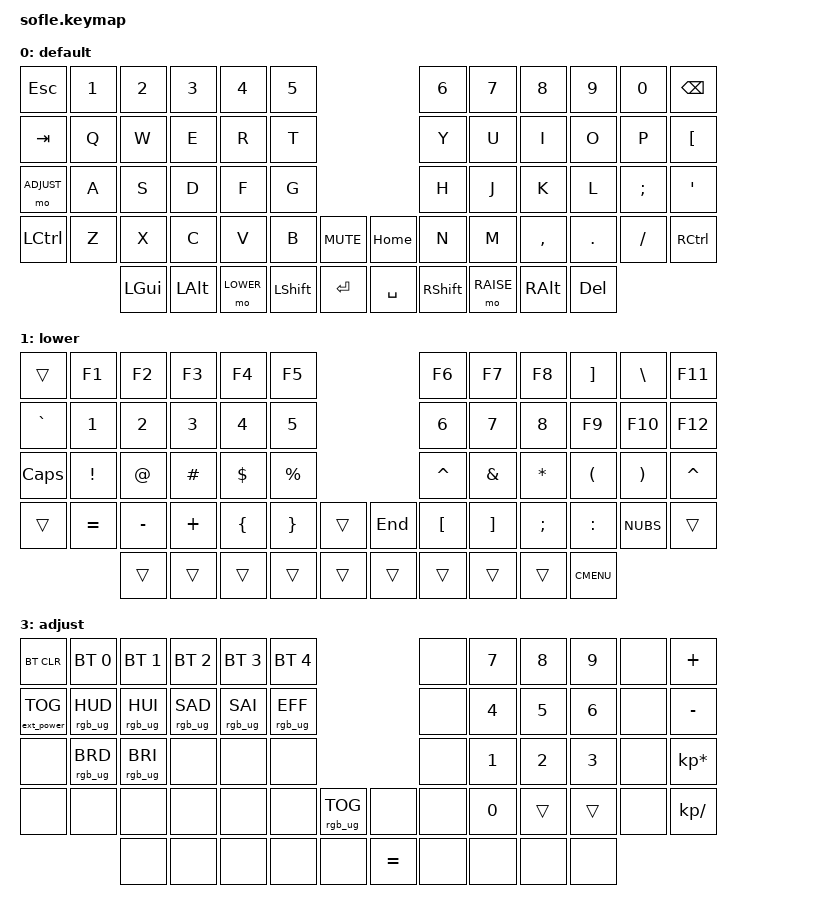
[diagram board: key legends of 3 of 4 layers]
/*
 * Copyright (c) 2020 The ZMK Contributors
 *
 * SPDX-License-Identifier: MIT
 */

#include <behaviors.dtsi>
#include <dt-bindings/zmk/keys.h>
#include <dt-bindings/zmk/bt.h>
#include <dt-bindings/zmk/rgb.h>
#include <dt-bindings/zmk/ext_power.h>

&left_encoder { resolution = <1>;};
&right_encoder { resolution = <1>;};

#define BASE 0
#define LOWER 1
#define RAISE 2
#define ADJUST 3

/ {

   // Activate ADJUST layer by pressing raise and lower
   // conditional_layers {
   //     compatible = "zmk,conditional-layers";
   //     adjust_layer {
   //         if-layers = <RAISE LOWER>;
   //         then-layer = <ADJUST>;
   //     };
   // };

    keymap {
        compatible = "zmk,keymap";

        default_layer {
            display-name = "default";
// ------------------------------------------------------------------------------------------------------------
// |  ESC  |  1  |  2  |  3   |  4   |  5   |                   |  6   |  7    |  8    |  9   |   0   | BKSPC |
// |  TAB  |  Q  |  W  |  E   |  R   |  T   |                   |  Y   |  U    |  I    |  O   |   P   |  []   |
// | ADJUST|  A  |  S  |  D   |  F   |  G   |                   |  H   |  J    |  K    |  L   |   ;   |   '   |
// | CTRL  |  Z  |  X  |  C   |  V   |  B   |  MUTE  |  |  HOME |  N   |  M    |  ,    |  .   |   /   | CTRL  |
//               | GUI | LALT | LOWER| SHIFT|  ENTER |  | SPACE | SHIFT| RAISE | RALT  | DEL  |
            bindings = <
&kp ESC   &kp N1 &kp N2   &kp N3   &kp N4    &kp N5                           &kp N6 &kp N7    &kp N8    &kp N9   &kp N0   &kp BSPC
&kp TAB   &kp Q  &kp W    &kp E    &kp R     &kp T                            &kp Y  &kp U     &kp I     &kp O    &kp P    &kp LBKT
&mo ADJUST &kp A  &kp S    &kp D    &kp F     &kp G                            &kp H  &kp J     &kp K     &kp L    &kp SEMI &kp APOS
&kp LCTRL &kp Z  &kp X    &kp C    &kp V     &kp B      &kp C_MUTE &kp HOME   &kp N  &kp M     &kp COMMA &kp DOT  &kp FSLH &kp RCTRL
                 &kp LGUI &kp LALT &mo LOWER &kp LSHFT  &kp RET   &kp SPACE  &kp RSHFT  &mo RAISE &kp RALT  &kp DEL
            >;

             sensor-bindings = <&inc_dec_kp C_VOL_DN C_VOL_UP &inc_dec_kp UP DOWN>;
        };

        lower_layer {
            display-name = "lower";
// TODO: Some binds are waiting for shifted keycode support.
// ------------------------------------------------------------------------------------------------------------
// |       |  F1 |  F2 |  F3  |  F4  |  F5  |                   |  F6  |  F7   |  F8   |  [   |   ]   |  F11  |
// |   `   |  1  |  2  |  3   |  4   |  5   |                   |   6  |  7    |  8    |  F9  |   F10 |  F12  |
// | CAPS  |  !  |  @  |  #   |  $   |  %   |                   |  ^   |  &    |  *    |  (   |   )   |   ¨   |
// |       |  =  |  -  |  +   |  {   |  }   |        |  |  END  |  [   |  ]    |  ;    |  :   |   \   |       |
//               |     |      |      |      |        |  |       |      |       |       | MENU |
            bindings = <
&trans    &kp F1    &kp F2    &kp F3      &kp F4    &kp F5                    &kp F6    &kp F7   &kp F8    &kp RBKT  &kp BSLH  &kp F11
&kp GRAVE &kp N1    &kp N2    &kp N3      &kp N4    &kp N5                    &kp N6    &kp N7  &kp N8    &kp F9    &kp F10   &kp F12
&kp CAPS  &kp EXCL  &kp AT    &kp HASH    &kp DLLR  &kp PRCNT                 &kp CARET &kp AMPS &kp ASTRK &kp LPAR  &kp RPAR  &kp CARET
&trans    &kp EQUAL &kp MINUS &kp PLUS    &kp LBRC  &kp RBRC   &trans &kp END &kp LBKT  &kp RBKT &kp SEMI  &kp COLON &kp NUBS  &trans
                    &trans    &trans      &trans    &trans     &trans &trans  &trans    &trans   &trans    &kp K_CMENU
            >;

            sensor-bindings = <&inc_dec_kp C_VOL_DN C_VOL_UP &inc_dec_kp LEFT RIGHT>;
        };

        raise_layer {
            display-name = "raise";
// ------------------------------------------------------------------------------------------------------------
// |  ´   | BT1  | BT2  |  BT3  |  BT4  |  BT5 |                |      |      |  PSCR |  {   |   }   |       |
// | BTCLR| INS  | PSCR | GUI   |       |      |                | PGUP | HOME |   ^   | END  |       |   _   |
// | CAPS | ALT  | CTRL | SHIFT |       | CAPS |                | PGDN |   <- |   v   |  ->  |  DEL  | BKSPC |
// |      | UNDO | CUT  | COPY  | PASTE |      |PL_PA |  |      |      |      |       |      |   |   |       |
//                |      |       |       |      |      |  |      |      |      |       |      |
            bindings = <
&kp GRAVE  &bt BT_SEL 0 &bt BT_SEL 1 &bt BT_SEL 2 &bt BT_SEL 3 &bt BT_SEL 4                   &trans    &trans    &kp PSCRN &kp RBRC  &kp PIPE  &trans
&bt BT_CLR &kp INS      &kp PSCRN    &kp K_CMENU  &trans       &trans                         &kp PG_UP &kp HOME  &kp UP   &kp END   &kp N0    &kp UNDER
&kp CAPS   &kp LALT     &kp LCTRL    &kp LSHFT    &trans       &kp CLCK                       &kp PG_DN &kp LEFT  &kp DOWN &kp RIGHT &kp DEL   &kp BSPC
&kp &trans &kp K_UNDO   &kp K_CUT    &kp K_COPY   &kp K_PASTE  &trans        &kp C_PP &trans  &trans    &trans    &trans   &trans    &kp PIPE2  &trans
                        &trans       &trans       &trans       &trans        &trans   &trans  &trans    &trans    &trans   &trans
            >;

            sensor-bindings = <&inc_dec_kp C_NEXT C_PREV &inc_dec_kp PG_UP PG_DN>;
        };

        adjust_layer {
// ----------------------------------------------------------------------------------------------------------------------------
// | BTCLR  |  BT1    |  BT2    |   BT3   |   BT4   |   BT5   |                  |      |   7  |   8   |   9   |       |   +   |
// | EXTPWR | RGB_HUD | RGB_HUI | RGB_SAD | RGB_SAI | RGB_EFF |                  |      |   4  |   5   |   6   |       |   -   |
// |        | RGB_BRD | RGB_BRI |         |         |         |                  |      |   1  |   2   |   3   |       |   *   |
// |        |         |         |         |         |         | RGB_TOG | |      |      |   0  |       |       |       |    /  |
//                    |         |         |         |         |         | |   =  |      |      |       |      |
            display-name = "adjust";
            bindings = <
&bt BT_CLR        &bt BT_SEL 0    &bt BT_SEL 1    &bt BT_SEL 2    &bt BT_SEL 3    &bt BT_SEL 4                            &none &kp N7 &kp N8 &kp N9 &none &kp PLUS
&ext_power EP_TOG &rgb_ug RGB_HUD &rgb_ug RGB_HUI &rgb_ug RGB_SAD &rgb_ug RGB_SAI &rgb_ug RGB_EFF                         &none &kp N4 &kp N5 &kp N6 &none &kp MINUS
&none             &rgb_ug RGB_BRD &rgb_ug RGB_BRI &none           &none           &none                                   &none &kp N1 &kp N2 &kp N3 &none &kp KP_MULTIPLY
&none             &none           &none           &none           &none           &none            &rgb_ug RGB_TOG &none  &none &kp N0 &trans &trans &none &kp KP_DIVIDE
                                  &none           &none           &none           &none            &none           &kp EQUAL  &none &none &none &none
        >;
        };

    };
};
